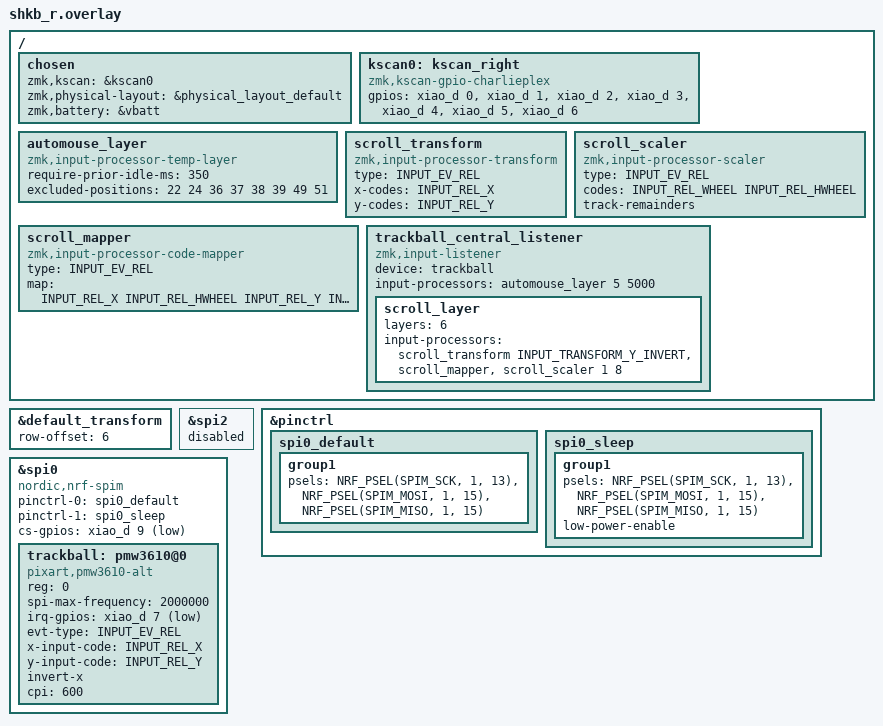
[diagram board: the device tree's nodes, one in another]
#include "shkb.dtsi"
#include <dt-bindings/input/input-event-codes.h>
#include <dt-bindings/zmk/input_transform.h>

/ {
    chosen {
        zmk,kscan = &kscan0;
        zmk,physical-layout = &physical_layout_default;
        zmk,battery = &vbatt;
    };

    kscan0: kscan_right {
        compatible = "zmk,kscan-gpio-charlieplex";
        gpios
            = <&xiao_d 0 0>
            , <&xiao_d 1 0>
            , <&xiao_d 2 0>
            , <&xiao_d 3 0>
            , <&xiao_d 4 0>
            , <&xiao_d 5 0>
            , <&xiao_d 6 0>
            ;
    };

    automouse_layer: automouse_layer {
        compatible = "zmk,input-processor-temp-layer";
        #input-processor-cells = <2>;
        require-prior-idle-ms = <350>; /* キー押下後、何msオートマウスレイヤに入らないようにするか、誤爆防止 */
        excluded-positions = <22 24 36 37 38 39 49 51>;
    };

    scroll_transform: scroll_transform {
        compatible = "zmk,input-processor-transform";
        #input-processor-cells = <1>;
        type = <INPUT_EV_REL>;
        x-codes = <INPUT_REL_X>;
        y-codes = <INPUT_REL_Y>;
    };

    scroll_mapper: scroll_mapper {
        compatible = "zmk,input-processor-code-mapper";
        #input-processor-cells = <0>;
        type = <INPUT_EV_REL>;
        map = <INPUT_REL_X INPUT_REL_HWHEEL
               INPUT_REL_Y INPUT_REL_WHEEL>;
    };

    scroll_scaler: scroll_scaler {
        compatible = "zmk,input-processor-scaler";
        #input-processor-cells = <2>;
        type = <INPUT_EV_REL>;
        codes = <INPUT_REL_WHEEL INPUT_REL_HWHEEL>;
        track-remainders;
    };

    /* Right half is the split central and hosts the trackball directly, so
     * events are consumed locally instead of relaying over the
     * peripheral->central BLE hop (see shkb_l.overlay). */
    trackball_central_listener: trackball_central_listener {
        compatible = "zmk,input-listener";
        device = <&trackball>;
        input-processors = <&automouse_layer 5 5000>;

        scroll_layer {
            layers = <6>;
            input-processors = <&scroll_transform INPUT_TRANSFORM_Y_INVERT &scroll_mapper &scroll_scaler 1 8>;
        };
    };
};

/* Right half has no split relay to feed in normal mode – the trackball is
 * consumed locally by trackball_central_listener above. */
/delete-node/ &trackball_peripheral_split;

/* Shift right-half kscan rows by 6 to avoid lookup table collision with
 * the left side, which uses rows 0-5. Right charlieplex pins 0-6
 * (rows 0-6) map to effective rows 6-12 in the combined transform. */
&default_transform {
    row-offset = <6>;
};

/* spi2 (xiao_spi) uses the same GPIO pins as our spi0 (P1.13, P1.15).
 * Disable spi2 to avoid pinctrl conflict. */
&spi2 { status = "disabled"; };

&pinctrl {
    spi0_default: spi0_default {
        group1 {
            psels = <NRF_PSEL(SPIM_SCK, 1, 13)>,
                    <NRF_PSEL(SPIM_MOSI, 1, 15)>,
                    <NRF_PSEL(SPIM_MISO, 1, 15)>;
        };
    };

    spi0_sleep: spi0_sleep {
        group1 {
            psels = <NRF_PSEL(SPIM_SCK, 1, 13)>,
                    <NRF_PSEL(SPIM_MOSI, 1, 15)>,
                    <NRF_PSEL(SPIM_MISO, 1, 15)>;
            low-power-enable;
        };
    };
};

&spi0 {
    compatible = "nordic,nrf-spim";
    status = "okay";
    pinctrl-0 = <&spi0_default>;
    pinctrl-1 = <&spi0_sleep>;
    pinctrl-names = "default", "sleep";
    cs-gpios = <&xiao_d 9 GPIO_ACTIVE_LOW>;

    trackball: pmw3610@0 {
        compatible = "pixart,pmw3610-alt";
        reg = <0>;
        spi-max-frequency = <2000000>;
        irq-gpios = <&xiao_d 7 GPIO_ACTIVE_LOW>;
        evt-type = <INPUT_EV_REL>;
        x-input-code = <INPUT_REL_X>;
        y-input-code = <INPUT_REL_Y>;
        invert-x;

        cpi = <600>;
    };
};
